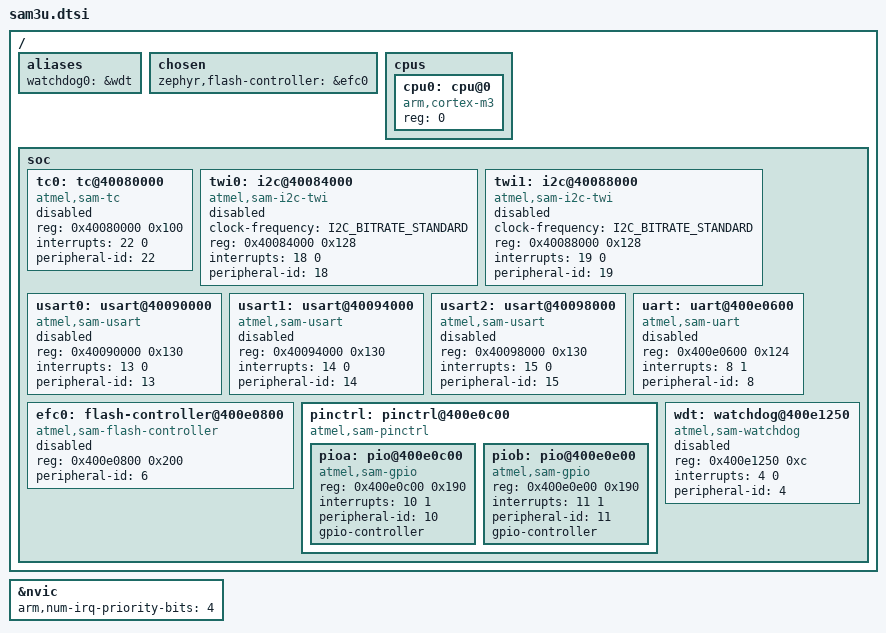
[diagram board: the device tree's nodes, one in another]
/*
 * Copyright (c) 2023 Chen Xingyu <hi@xingrz.me>
 *
 * SPDX-License-Identifier: Apache-2.0
 */

#include <mem.h>
#include <freq.h>
#include <arm/armv7-m.dtsi>
#include <zephyr/dt-bindings/i2c/i2c.h>

/ {
	aliases {
		watchdog0 = &wdt;
	};

	chosen {
		zephyr,flash-controller = &efc0;
	};

	cpus {
		#address-cells = <1>;
		#size-cells = <0>;

		cpu0: cpu@0 {
			device_type = "cpu";
			compatible = "arm,cortex-m3";
			reg = <0>;
		};
	};

	soc {
		tc0: tc@40080000 {
			compatible = "atmel,sam-tc";
			reg = <0x40080000 0x100>;
			interrupts = <22 0>;
			peripheral-id = <22>;
			status = "disabled";
		};

		twi0: i2c@40084000 {
			compatible = "atmel,sam-i2c-twi";
			clock-frequency = <I2C_BITRATE_STANDARD>;
			reg = <0x40084000 0x128>;
			interrupts = <18 0>;
			peripheral-id = <18>;
			status = "disabled";
			#address-cells = <1>;
			#size-cells = <0>;
		};

		twi1: i2c@40088000 {
			compatible = "atmel,sam-i2c-twi";
			clock-frequency = <I2C_BITRATE_STANDARD>;
			reg = <0x40088000 0x128>;
			interrupts = <19 0>;
			peripheral-id = <19>;
			status = "disabled";
			#address-cells = <1>;
			#size-cells = <0>;
		};

		usart0: usart@40090000 {
			compatible = "atmel,sam-usart";
			reg = <0x40090000 0x130>;
			interrupts = <13 0>;
			peripheral-id = <13>;
			status = "disabled";
		};

		usart1: usart@40094000 {
			compatible = "atmel,sam-usart";
			reg = <0x40094000 0x130>;
			interrupts = <14 0>;
			peripheral-id = <14>;
			status = "disabled";
		};

		usart2: usart@40098000 {
			compatible = "atmel,sam-usart";
			reg = <0x40098000 0x130>;
			interrupts = <15 0>;
			peripheral-id = <15>;
			status = "disabled";
		};

		uart: uart@400e0600 {
			compatible = "atmel,sam-uart";
			reg = <0x400e0600 0x124>;
			interrupts = <8 1>;
			peripheral-id = <8>;
			status = "disabled";
		};

		efc0: flash-controller@400e0800 {
			compatible = "atmel,sam-flash-controller";
			reg = <0x400e0800 0x200>;
			peripheral-id = <6>;

			#address-cells = <1>;
			#size-cells = <1>;

			status = "disabled";
		};

		pinctrl: pinctrl@400e0c00 {
			compatible = "atmel,sam-pinctrl";
			#address-cells = <1>;
			#size-cells = <1>;
			ranges = <0x400e0c00 0x400e0c00 0xc00>;

			pioa: pio@400e0c00 {
				compatible = "atmel,sam-gpio";
				reg = <0x400e0c00 0x190>;
				interrupts = <10 1>;
				peripheral-id = <10>;
				gpio-controller;
				#gpio-cells = <2>;
				#atmel,pin-cells = <2>;
			};

			piob: pio@400e0e00 {
				compatible = "atmel,sam-gpio";
				reg = <0x400e0e00 0x190>;
				interrupts = <11 1>;
				peripheral-id = <11>;
				gpio-controller;
				#gpio-cells = <2>;
				#atmel,pin-cells = <2>;
			};
		};

		wdt: watchdog@400e1250 {
			compatible = "atmel,sam-watchdog";
			reg = <0x400e1250 0xc>;
			interrupts = <4 0>;
			peripheral-id = <4>;
			status = "disabled";
		};
	};
};

&nvic {
	arm,num-irq-priority-bits = <4>;
};
